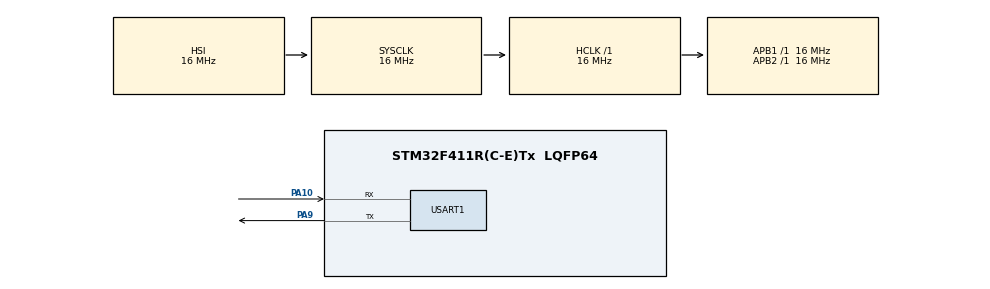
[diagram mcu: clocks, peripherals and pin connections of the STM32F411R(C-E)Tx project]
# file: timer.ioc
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Mcu.Family=STM32F4
Mcu.Name=STM32F411R(C-E)Tx
Mcu.Package=LQFP64
NVIC.PriorityGroup=NVIC_PRIORITYGROUP_4
NVIC.USART1_IRQn=true\:0\:0\:false\:false\:true\:true
PA10.Mode=Asynchronous
PA10.Signal=USART1_RX
PA9.Mode=Asynchronous
PA9.Signal=USART1_TX
ProjectManager.HeapSize=0x200
ProjectManager.StackSize=0x400
ProjectManager.TargetToolchain=Makefile
RCC.AHBFreq_Value=16000000
RCC.APB1Freq_Value=16000000
RCC.APB2Freq_Value=16000000
RCC.CortexFreq_Value=16000000
RCC.HSE_VALUE=25000000
RCC.HSI_VALUE=16000000
RCC.LSE_VALUE=32768
RCC.SYSCLKFreq_VALUE=16000000
RCC.VCOOutputFreq_Value=192000000
USART1.VirtualMode=VM_ASYNC
VP_TIM1_VS_ClockSourceINT.Mode=Internal
board=custom

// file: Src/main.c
/* USER CODE BEGIN Header */

// This program contains:
// 1. A part about counting 1,2,3...seconds with timers (Am I interrupted when I need?)
// 2. A part about (clock()-clock())/1000 (How much has the function lasted?)

/**
  ******************************************************************************
  * @file           : main.c
  * @brief          : Main program body
  ******************************************************************************
  ** This notice applies to any and all portions of this file
  * that are not between comment pairs USER CODE BEGIN and
  * USER CODE END. Other portions of this file, whether
  * inserted by the user or by software development tools
  * are owned by their respective copyright owners.
  *
  * COPYRIGHT(c) 2019 STMicroelectronics
  *
  * Redistribution and use in source and binary forms, with or without modification,
  * are permitted provided that the following conditions are met:
  *   1. Redistributions of source code must retain the above copyright notice,
  *      this list of conditions and the following disclaimer.
  *   2. Redistributions in binary form must reproduce the above copyright notice,
  *      this list of conditions and the following disclaimer in the documentation
  *      and/or other materials provided with the distribution.
  *   3. Neither the name of STMicroelectronics nor the names of its contributors
  *      may be used to endorse or promote products derived from this software
  *      without specific prior written permission.
  *
  * THIS SOFTWARE IS PROVIDED BY THE COPYRIGHT HOLDERS AND CONTRIBUTORS "AS IS"
  * AND ANY EXPRESS OR IMPLIED WARRANTIES, INCLUDING, BUT NOT LIMITED TO, THE
  * IMPLIED WARRANTIES OF MERCHANTABILITY AND FITNESS FOR A PARTICULAR PURPOSE ARE
  * DISCLAIMED. IN NO EVENT SHALL THE COPYRIGHT HOLDER OR CONTRIBUTORS BE LIABLE
  * FOR ANY DIRECT, INDIRECT, INCIDENTAL, SPECIAL, EXEMPLARY, OR CONSEQUENTIAL
  * DAMAGES (INCLUDING, BUT NOT LIMITED TO, PROCUREMENT OF SUBSTITUTE GOODS OR
  * SERVICES; LOSS OF USE, DATA, OR PROFITS; OR BUSINESS INTERRUPTION) HOWEVER
  * CAUSED AND ON ANY THEORY OF LIABILITY, WHETHER IN CONTRACT, STRICT LIABILITY,
  * OR TORT (INCLUDING NEGLIGENCE OR OTHERWISE) ARISING IN ANY WAY OUT OF THE USE
  * OF THIS SOFTWARE, EVEN IF ADVISED OF THE POSSIBILITY OF SUCH DAMAGE.
  *
  ******************************************************************************
  */
/* USER CODE END Header */

#include "main.h"
#include "stm32f4xx_hal_tim.h"

/* USER CODE BEGIN PD */
#define EXE_WAIT 0 /* run func1 or 2? */
/* USER CODE END PD */

TIM_HandleTypeDef htim1;
UART_HandleTypeDef huart1;
unsigned char buffer[128] = "Begin\r\n";

void SystemClock_Config(void);
static void MX_GPIO_Init(void);
static void MX_TIM1_Init(void);
static void MX_USART1_UART_Init(void);

static void func1();
static void func2();

int main(void)
{

  /* MCU Configuration--------------------------------------------------------*/

  /* Reset of all peripherals, Initializes the Flash interface and the Systick. */
  HAL_Init();

  /* Configure the system clock */
  SystemClock_Config();

  /* Initialize all configured peripherals */
  MX_GPIO_Init();
  MX_TIM1_Init();
  MX_USART1_UART_Init();

  /* Infinite loop */
  /* USER CODE BEGIN WHILE */
  HAL_TIM_Base_Start(&htim1);
  if (EXE_WAIT)
    func1();
  else
    func2();
  /* USER CODE END 3 */
}

/**
  * Test (clock() - clock()) / CLOCK_PER_SEC
  */
void func1() {
  sprintf(buffer, "while - Begin\r\n");
  HAL_UART_Transmit(&huart1, buffer, sizeof(buffer), HAL_MAX_DELAY);

  while (1)
  {
    // see TIM1 callback
  }
}

/**
  * Test delay with timer (polling)
  */
void func2() {
  while (1)
  {
    /* USER CODE END WHILE */
    sprintf(buffer, "\r\nwhile - Begin\r\n");
    HAL_UART_Transmit(&huart1, buffer, sizeof(buffer), HAL_MAX_DELAY);

    // Am I really measuring microseconds?
    int prevReading = __HAL_TIM_GetCounter(&htim1);

    HAL_Delay(1000); // 1s

    int curReading  = __HAL_TIM_GetCounter(&htim1);

    //HAL_TIM_Base_Stop(&htim1);

    sprintf(buffer, "time elapsed %d second\r\n", curReading - prevReading);
    HAL_UART_Transmit(&huart1, buffer, sizeof(buffer), HAL_MAX_DELAY);

  }
}

void SystemClock_Config(void)
{
  RCC_OscInitTypeDef RCC_OscInitStruct = {0};
  RCC_ClkInitTypeDef RCC_ClkInitStruct = {0};

  /**Configure the main internal regulator output voltage
  */
  __HAL_RCC_PWR_CLK_ENABLE();
  __HAL_PWR_VOLTAGESCALING_CONFIG(PWR_REGULATOR_VOLTAGE_SCALE1);
  /**Initializes the CPU, AHB and APB busses clocks
  */
  RCC_OscInitStruct.OscillatorType = RCC_OSCILLATORTYPE_HSI;
  RCC_OscInitStruct.HSIState = RCC_HSI_ON;
  RCC_OscInitStruct.HSICalibrationValue = RCC_HSICALIBRATION_DEFAULT;
  RCC_OscInitStruct.PLL.PLLState = RCC_PLL_NONE;
  if (HAL_RCC_OscConfig(&RCC_OscInitStruct) != HAL_OK)
  {
    Error_Handler();
  }
  /**Initializes the CPU, AHB and APB busses clocks
  */
  RCC_ClkInitStruct.ClockType = RCC_CLOCKTYPE_HCLK|RCC_CLOCKTYPE_SYSCLK
                              |RCC_CLOCKTYPE_PCLK1|RCC_CLOCKTYPE_PCLK2;
  RCC_ClkInitStruct.SYSCLKSource = RCC_SYSCLKSOURCE_HSI;
  RCC_ClkInitStruct.AHBCLKDivider = RCC_SYSCLK_DIV1;
  RCC_ClkInitStruct.APB1CLKDivider = RCC_HCLK_DIV1;
  RCC_ClkInitStruct.APB2CLKDivider = RCC_HCLK_DIV1;

  if (HAL_RCC_ClockConfig(&RCC_ClkInitStruct, FLASH_LATENCY_0) != HAL_OK)
  {
    Error_Handler();
  }
}

static void MX_TIM1_Init(void)
{

  TIM_ClockConfigTypeDef sClockSourceConfig = {0};
  TIM_MasterConfigTypeDef sMasterConfig = {0};

  htim1.Instance = TIM1;
  if (EXE_WAIT)
    htim1.Init.Prescaler = 15999; // 16MHz
  else
    htim1.Init.Prescaler = 15999999999; // 16MHz
  if (EXE_WAIT)
    htim1.Init.Period = 999; // 1 s
  else
    htim1.Init.Period = 9;  // 1 us
  htim1.Init.CounterMode = TIM_COUNTERMODE_UP;
  htim1.Init.ClockDivision = TIM_CLOCKDIVISION_DIV1;
  htim1.Init.RepetitionCounter = 0;
  if (HAL_TIM_Base_Init(&htim1) != HAL_OK)
  {
    Error_Handler();
  }
  sClockSourceConfig.ClockSource = TIM_CLOCKSOURCE_INTERNAL;
  if (HAL_TIM_ConfigClockSource(&htim1, &sClockSourceConfig) != HAL_OK)
  {
    Error_Handler();
  }
  sMasterConfig.MasterOutputTrigger = TIM_TRGO_RESET;
  sMasterConfig.MasterSlaveMode = TIM_MASTERSLAVEMODE_DISABLE;
  if (HAL_TIMEx_MasterConfigSynchronization(&htim1, &sMasterConfig) != HAL_OK)
  {
    Error_Handler();
  }
  /* USER CODE BEGIN TIM1_Init 2 */
  if (EXE_WAIT) {
    HAL_NVIC_SetPriority(TIM1_UP_TIM10_IRQn, 0, 0);
    HAL_NVIC_EnableIRQ(TIM1_UP_TIM10_IRQn);

    HAL_TIM_Base_Start_IT(&htim1); //Start the timer
  }
  /* USER CODE END TIM1_Init 2 */

}

void TIM1_UP_TIM10_IRQHandler(void) {
  HAL_TIM_IRQHandler(&htim1);
}

int i = 0;
void HAL_TIM_PeriodElapsedCallback(TIM_HandleTypeDef *htim) {
  // This callback is automatically called by the HAL on the UEV event
  if(htim->Instance == TIM1) {
    sprintf(buffer, "%d\r\n",i++);
    HAL_UART_Transmit(&huart1, buffer, sizeof(buffer), HAL_MAX_DELAY);
  }
}

static void MX_USART1_UART_Init(void)
{

  huart1.Instance = USART1;
  huart1.Init.BaudRate = 115200;
  huart1.Init.WordLength = UART_WORDLENGTH_8B;
  huart1.Init.StopBits = UART_STOPBITS_1;
  huart1.Init.Parity = UART_PARITY_NONE;
  huart1.Init.Mode = UART_MODE_TX_RX;
  huart1.Init.HwFlowCtl = UART_HWCONTROL_NONE;
  huart1.Init.OverSampling = UART_OVERSAMPLING_16;
  if (HAL_UART_Init(&huart1) != HAL_OK)
  {
    Error_Handler();
  }

}

static void MX_GPIO_Init(void)
{

  /* GPIO Ports Clock Enable */
  __HAL_RCC_GPIOA_CLK_ENABLE();

}

void Error_Handler(void)
{
}

/************************ (C) COPYRIGHT STMicroelectronics *****END OF FILE****/
